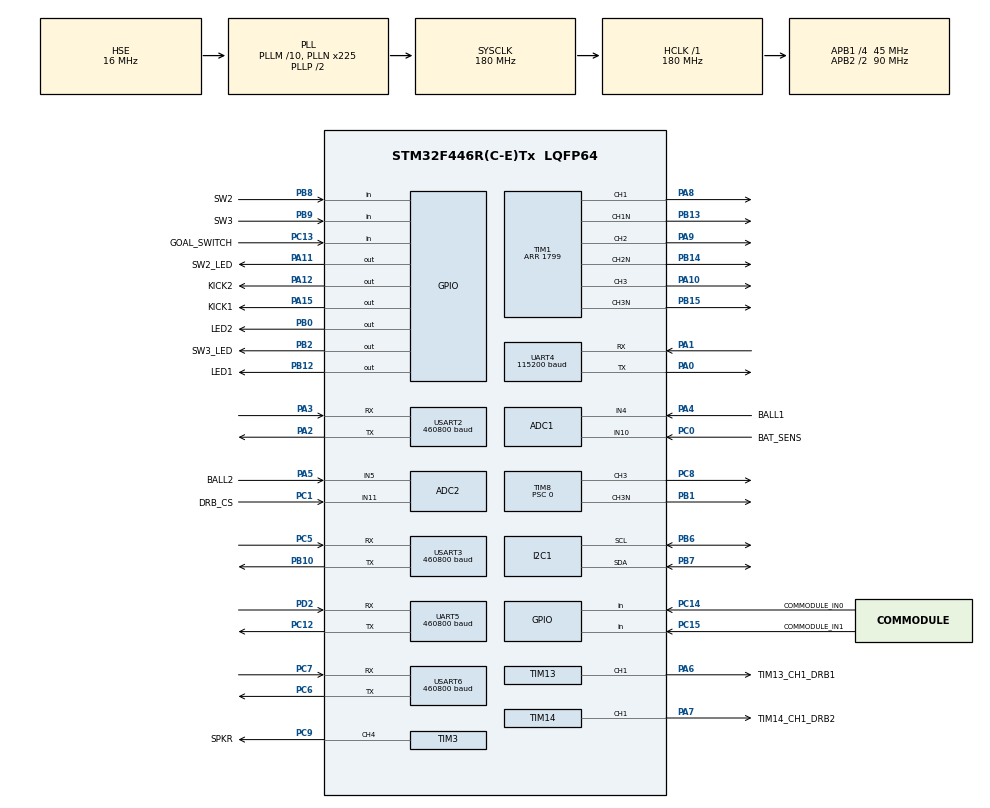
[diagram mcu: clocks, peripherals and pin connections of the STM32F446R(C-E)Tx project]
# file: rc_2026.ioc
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ADC1.Channel-0\#ChannelRegularConversion=ADC_CHANNEL_4
ADC1.ClockPrescaler=ADC_CLOCK_SYNC_PCLK_DIV4
ADC1.NbrOfConversionFlag=1
ADC1.Rank-0\#ChannelRegularConversion=1
ADC1.SamplingTime-0\#ChannelRegularConversion=ADC_SAMPLETIME_3CYCLES
ADC1.master=1
ADC2.Channel-0\#ChannelRegularConversion=ADC_CHANNEL_5
ADC2.ClockPrescaler=ADC_CLOCK_SYNC_PCLK_DIV4
ADC2.NbrOfConversionFlag=1
ADC2.Rank-0\#ChannelRegularConversion=1
ADC2.SamplingTime-0\#ChannelRegularConversion=ADC_SAMPLETIME_3CYCLES
Dma.Request0=USART6_RX
Dma.USART6_RX.0.Direction=DMA_PERIPH_TO_MEMORY
Dma.USART6_RX.0.FIFOMode=DMA_FIFOMODE_DISABLE
Dma.USART6_RX.0.Instance=DMA2_Stream1
Dma.USART6_RX.0.MemDataAlignment=DMA_MDATAALIGN_BYTE
Dma.USART6_RX.0.MemInc=DMA_MINC_ENABLE
Dma.USART6_RX.0.Mode=DMA_NORMAL
Dma.USART6_RX.0.PeriphDataAlignment=DMA_PDATAALIGN_BYTE
Dma.USART6_RX.0.PeriphInc=DMA_PINC_DISABLE
Dma.USART6_RX.0.Priority=DMA_PRIORITY_LOW
Mcu.Family=STM32F4
Mcu.Name=STM32F446R(C-E)Tx
Mcu.Package=LQFP64
NVIC.DMA2_Stream1_IRQn=true\:0\:0\:false\:false\:true\:false\:true\:true
NVIC.PriorityGroup=NVIC_PRIORITYGROUP_4
NVIC.RCC_IRQn=true\:0\:0\:false\:false\:true\:true\:false\:true
NVIC.TIM1_BRK_TIM9_IRQn=true\:0\:0\:false\:false\:true\:true\:true\:true
NVIC.TIM6_DAC_IRQn=true\:15\:0\:true\:false\:true\:true\:true\:true
NVIC.TIM8_TRG_COM_TIM14_IRQn=true\:0\:0\:false\:false\:true\:true\:true\:true
NVIC.UART4_IRQn=true\:0\:0\:false\:false\:true\:true\:true\:true
NVIC.UART5_IRQn=true\:0\:0\:false\:false\:true\:true\:true\:true
NVIC.USART2_IRQn=true\:1\:0\:true\:false\:true\:true\:true\:true
NVIC.USART3_IRQn=true\:0\:0\:false\:false\:true\:true\:true\:true
NVIC.USART6_IRQn=true\:0\:0\:false\:false\:true\:true\:true\:true
PA0-WKUP.Mode=Asynchronous
PA0-WKUP.Signal=UART4_TX
PA1.Mode=Asynchronous
PA1.Signal=UART4_RX
PA10.Signal=S_TIM1_CH3
PA11.GPIO_Label=SW2_LED
PA11.Signal=GPIO_Output
PA12.GPIO_Label=KICK2
PA12.GPIO_ModeDefaultOutputPP=GPIO_MODE_OUTPUT_PP
PA12.GPIO_PuPd=GPIO_NOPULL
PA12.PinState=GPIO_PIN_RESET
PA12.Signal=GPIO_Output
PA13.Mode=Serial_Wire
PA13.Signal=SYS_JTMS-SWDIO
PA14.Mode=Serial_Wire
PA14.Signal=SYS_JTCK-SWCLK
PA15.GPIO_Label=KICK1
PA15.GPIO_ModeDefaultOutputPP=GPIO_MODE_OUTPUT_PP
PA15.GPIO_PuPd=GPIO_NOPULL
PA15.Signal=GPIO_Output
PA2.Mode=Asynchronous
PA2.Signal=USART2_TX
PA3.Mode=Asynchronous
PA3.Signal=USART2_RX
PA4.GPIO_Label=BALL1
PA4.Signal=ADCx_IN4
PA5.GPIO_Label=BALL2
PA5.Signal=ADCx_IN5
PA6.GPIO_Label=TIM13_CH1_DRB1
PA6.Signal=S_TIM13_CH1
PA7.GPIO_Label=TIM14_CH1_DRB2
PA7.Signal=S_TIM14_CH1
PA8.Signal=S_TIM1_CH1
PA9.Signal=S_TIM1_CH2
PB0.GPIO_Label=LED2
PB0.Signal=GPIO_Output
PB1.Mode=PWM Generation3 CH3 CH3N
PB1.Signal=TIM8_CH3N
PB10.Mode=Asynchronous
PB10.Signal=USART3_TX
PB12.GPIO_Label=LED1
PB12.Signal=GPIO_Output
PB13.Mode=PWM Generation1 CH1 CH1N
PB13.Signal=TIM1_CH1N
PB14.Mode=PWM Generation2 CH2 CH2N
PB14.Signal=TIM1_CH2N
PB15.Mode=PWM Generation3 CH3 CH3N
PB15.Signal=TIM1_CH3N
PB2.GPIO_Label=SW3_LED
PB2.Signal=GPIO_Output
PB6.Mode=I2C
PB6.Signal=I2C1_SCL
PB7.Mode=I2C
PB7.Signal=I2C1_SDA
PB8.GPIO_Label=SW2
PB8.Signal=GPIO_Input
PB9.GPIO_Label=SW3
PB9.Signal=GPIO_Input
PC0.GPIO_Label=BAT_SENS
PC0.Signal=ADCx_IN10
PC1.GPIO_Label=DRB_CS
PC1.Signal=ADCx_IN11
PC12.Mode=Asynchronous
PC12.Signal=UART5_TX
PC13.GPIO_Label=GOAL_SWITCH
PC13.Signal=GPIO_Input
PC14-OSC32_IN.GPIO_Label=COMMODULE_IN0
PC14-OSC32_IN.Signal=GPIO_Input
PC15-OSC32_OUT.GPIO_Label=COMMODULE_IN1
PC15-OSC32_OUT.Signal=GPIO_Input
PC5.Mode=Asynchronous
PC5.Signal=USART3_RX
PC6.GPIO_PuPd=GPIO_NOPULL
PC6.Mode=Asynchronous
PC6.Signal=USART6_TX
PC7.Mode=Asynchronous
PC7.Signal=USART6_RX
PC8.Signal=S_TIM8_CH3
PC9.GPIO_Label=SPKR
PC9.Signal=S_TIM3_CH4
PD2.Mode=Asynchronous
PD2.Signal=UART5_RX
PH0-OSC_IN.Mode=HSE-External-Oscillator
PH0-OSC_IN.Signal=RCC_OSC_IN
PH1-OSC_OUT.Mode=HSE-External-Oscillator
PH1-OSC_OUT.Signal=RCC_OSC_OUT
ProjectManager.HeapSize=0x200
ProjectManager.StackSize=0x400
ProjectManager.TargetToolchain=STM32CubeIDE
RCC.AHBFreq_Value=180000000
RCC.APB1CLKDivider=RCC_HCLK_DIV4
RCC.APB1Freq_Value=45000000
RCC.APB1TimFreq_Value=90000000
RCC.APB2CLKDivider=RCC_HCLK_DIV2
RCC.APB2Freq_Value=90000000
RCC.APB2TimFreq_Value=180000000
RCC.CortexFreq_Value=180000000
RCC.HCLKFreq_Value=180000000
RCC.HSE_Timout=5000
RCC.HSE_VALUE=16000000
RCC.HSICalibrationValue=31
RCC.PLLM=10
RCC.PLLN=225
RCC.PLLSAIM=20
RCC.PLLSourceVirtual=RCC_PLLSOURCE_HSE
RCC.SYSCLKFreq_VALUE=180000000
RCC.SYSCLKSource=RCC_SYSCLKSOURCE_PLLCLK
RCC.USBFreq_Value=180000000
RCC.VCOOutputFreq_Value=360000000
SH.ADCx_IN10.0=ADC1_IN10,IN10
SH.ADCx_IN11.0=ADC2_IN11,IN11
SH.ADCx_IN4.0=ADC1_IN4,IN4
SH.ADCx_IN5.0=ADC2_IN5,IN5
SH.S_TIM13_CH1.0=TIM13_CH1,PWM Generation1 CH1
SH.S_TIM14_CH1.0=TIM14_CH1,PWM Generation1 CH1
SH.S_TIM1_CH1.0=TIM1_CH1,PWM Generation1 CH1 CH1N
SH.S_TIM1_CH2.0=TIM1_CH2,PWM Generation2 CH2 CH2N
SH.S_TIM1_CH3.0=TIM1_CH3,PWM Generation3 CH3 CH3N
SH.S_TIM3_CH4.0=TIM3_CH4,PWM Generation4 CH4
SH.S_TIM8_CH3.0=TIM8_CH3,PWM Generation3 CH3 CH3N
TIM1.Channel-PWM\ Generation1\ CH1\ CH1N=TIM_CHANNEL_1
TIM1.Channel-PWM\ Generation2\ CH2\ CH2N=TIM_CHANNEL_2
TIM1.Channel-PWM\ Generation3\ CH3\ CH3N=TIM_CHANNEL_3
TIM1.Period=1799
TIM12.Period=100
TIM12.Prescaler=45
TIM13.Channel=TIM_CHANNEL_1
TIM13.Period=100
TIM13.Prescaler=180
TIM14.Channel=TIM_CHANNEL_1
TIM14.Period=100
TIM14.Prescaler=180
TIM2.Period=100
TIM2.Prescaler=45
TIM3.Channel-PWM\ Generation4\ CH4=TIM_CHANNEL_4
TIM3.Period=369
TIM3.Prescaler=89
TIM4.Period=100
TIM4.Prescaler=45
TIM5.Period=65535
TIM5.Prescaler=90
TIM6.Period=200
TIM6.Prescaler=9000
TIM7.Prescaler=45000
TIM8.Channel-PWM\ Generation3\ CH3\ CH3N=TIM_CHANNEL_3
TIM8.Period=1799
TIM8.Prescaler=0
TIM9.Period=9999
TIM9.Prescaler=17999
UART4.BaudRate=115200
UART4.VirtualMode=Asynchronous
UART5.BaudRate=460800
UART5.VirtualMode=Asynchronous
USART2.BaudRate=460800
USART2.VirtualMode=VM_ASYNC
USART3.BaudRate=460800
USART3.VirtualMode=VM_ASYNC
USART6.BaudRate=460800
USART6.VirtualMode=VM_ASYNC
VP_TIM12_VS_ClockSourceINT.Mode=Internal
VP_TIM13_VS_ClockSourceINT.Mode=Enable_Timer
VP_TIM14_VS_ClockSourceINT.Mode=Enable_Timer
VP_TIM2_VS_ClockSourceINT.Mode=Internal
VP_TIM3_VS_ClockSourceINT.Mode=Internal
VP_TIM4_VS_ClockSourceINT.Mode=Internal
VP_TIM5_VS_ClockSourceINT.Mode=Internal
VP_TIM6_VS_ClockSourceINT.Mode=Enable_Timer
VP_TIM7_VS_ClockSourceINT.Mode=Enable_Timer
VP_TIM8_VS_ClockSourceINT.Mode=Internal
VP_TIM9_VS_ClockSourceINT.Mode=Internal
board=custom

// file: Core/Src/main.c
/* USER CODE BEGIN Header */
/**
  ******************************************************************************
  * @file           : main.c
  * @brief          : Main program body
  ******************************************************************************
  * @attention
  *
  * Copyright (c) 2026 STMicroelectronics.
  * All rights reserved.
  *
  * This software is licensed under terms that can be found in the LICENSE file
  * in the root directory of this software component.
  * If no LICENSE file comes with this software, it is provided AS-IS.
  *
  ******************************************************************************
  */
/* USER CODE END Header */
#include "main.h"

/* USER CODE BEGIN Includes */
  #include "rc_api.h"
  /* USER CODE END Includes */

ADC_HandleTypeDef hadc1;
ADC_HandleTypeDef hadc2;

I2C_HandleTypeDef hi2c1;

TIM_HandleTypeDef htim1;
TIM_HandleTypeDef htim2;
TIM_HandleTypeDef htim3;
TIM_HandleTypeDef htim4;
TIM_HandleTypeDef htim5;
TIM_HandleTypeDef htim6;
TIM_HandleTypeDef htim7;
TIM_HandleTypeDef htim8;
TIM_HandleTypeDef htim9;
TIM_HandleTypeDef htim12;
TIM_HandleTypeDef htim13;
TIM_HandleTypeDef htim14;

UART_HandleTypeDef huart4;
UART_HandleTypeDef huart5;
UART_HandleTypeDef huart2;
UART_HandleTypeDef huart3;
UART_HandleTypeDef huart6;
DMA_HandleTypeDef hdma_usart6_rx;

void SystemClock_Config(void);
static void MX_GPIO_Init(void);
static void MX_DMA_Init(void);
static void MX_UART4_Init(void);
static void MX_UART5_Init(void);
static void MX_USART2_UART_Init(void);
static void MX_USART3_UART_Init(void);
static void MX_USART6_UART_Init(void);
static void MX_TIM14_Init(void);
static void MX_TIM6_Init(void);
static void MX_TIM2_Init(void);
static void MX_TIM3_Init(void);
static void MX_TIM4_Init(void);
static void MX_TIM12_Init(void);
static void MX_ADC1_Init(void);
static void MX_ADC2_Init(void);
static void MX_TIM13_Init(void);
static void MX_TIM8_Init(void);
static void MX_TIM5_Init(void);
static void MX_TIM7_Init(void);
static void MX_I2C1_Init(void);
static void MX_TIM1_Init(void);
static void MX_TIM9_Init(void);

int main(void)
{

  /* MCU Configuration--------------------------------------------------------*/

  /* Reset of all peripherals, Initializes the Flash interface and the Systick. */
  HAL_Init();

  /* Configure the system clock */
  SystemClock_Config();

  /* Initialize all configured peripherals */
  MX_GPIO_Init();
  MX_DMA_Init();
  MX_UART4_Init();
  MX_UART5_Init();
  MX_USART2_UART_Init();
  MX_USART3_UART_Init();
  MX_USART6_UART_Init();
  MX_TIM14_Init();
  MX_TIM6_Init();
  MX_TIM2_Init();
  MX_TIM3_Init();
  MX_TIM4_Init();
  MX_TIM12_Init();
  MX_ADC1_Init();
  MX_ADC2_Init();
  MX_TIM13_Init();
  MX_TIM8_Init();
  MX_TIM5_Init();
  MX_TIM7_Init();
  MX_I2C1_Init();
  MX_TIM1_Init();
  MX_TIM9_Init();
  /* USER CODE BEGIN 2 */
  rc_init();
  /* USER CODE END 2 */

  /* Infinite loop */
  while (1)
  {

    /* USER CODE BEGIN 3 */
    rc_poll();
  }
  /* USER CODE END 3 */
}

void SystemClock_Config(void)
{
  RCC_OscInitTypeDef RCC_OscInitStruct = {0};
  RCC_ClkInitTypeDef RCC_ClkInitStruct = {0};

  /** Configure the main internal regulator output voltage
  */
  __HAL_RCC_PWR_CLK_ENABLE();
  __HAL_PWR_VOLTAGESCALING_CONFIG(PWR_REGULATOR_VOLTAGE_SCALE1);

  /** Initializes the RCC Oscillators according to the specified parameters
  * in the RCC_OscInitTypeDef structure.
  */
  RCC_OscInitStruct.OscillatorType = RCC_OSCILLATORTYPE_HSE;
  RCC_OscInitStruct.HSEState = RCC_HSE_ON;
  RCC_OscInitStruct.PLL.PLLState = RCC_PLL_ON;
  RCC_OscInitStruct.PLL.PLLSource = RCC_PLLSOURCE_HSE;
  RCC_OscInitStruct.PLL.PLLM = 10;
  RCC_OscInitStruct.PLL.PLLN = 225;
  RCC_OscInitStruct.PLL.PLLP = RCC_PLLP_DIV2;
  RCC_OscInitStruct.PLL.PLLQ = 2;
  RCC_OscInitStruct.PLL.PLLR = 2;
  if (HAL_RCC_OscConfig(&RCC_OscInitStruct) != HAL_OK)
  {
    Error_Handler();
  }

  /** Activate the Over-Drive mode
  */
  if (HAL_PWREx_EnableOverDrive() != HAL_OK)
  {
    Error_Handler();
  }

  /** Initializes the CPU, AHB and APB buses clocks
  */
  RCC_ClkInitStruct.ClockType = RCC_CLOCKTYPE_HCLK|RCC_CLOCKTYPE_SYSCLK
                              |RCC_CLOCKTYPE_PCLK1|RCC_CLOCKTYPE_PCLK2;
  RCC_ClkInitStruct.SYSCLKSource = RCC_SYSCLKSOURCE_PLLCLK;
  RCC_ClkInitStruct.AHBCLKDivider = RCC_SYSCLK_DIV1;
  RCC_ClkInitStruct.APB1CLKDivider = RCC_HCLK_DIV4;
  RCC_ClkInitStruct.APB2CLKDivider = RCC_HCLK_DIV2;

  if (HAL_RCC_ClockConfig(&RCC_ClkInitStruct, FLASH_LATENCY_5) != HAL_OK)
  {
    Error_Handler();
  }
}

static void MX_ADC1_Init(void)
{

  ADC_ChannelConfTypeDef sConfig = {0};

  /** Configure the global features of the ADC (Clock, Resolution, Data Alignment and number of conversion)
  */
  hadc1.Instance = ADC1;
  hadc1.Init.ClockPrescaler = ADC_CLOCK_SYNC_PCLK_DIV4;
  hadc1.Init.Resolution = ADC_RESOLUTION_12B;
  hadc1.Init.ScanConvMode = DISABLE;
  hadc1.Init.ContinuousConvMode = DISABLE;
  hadc1.Init.DiscontinuousConvMode = DISABLE;
  hadc1.Init.ExternalTrigConvEdge = ADC_EXTERNALTRIGCONVEDGE_NONE;
  hadc1.Init.ExternalTrigConv = ADC_SOFTWARE_START;
  hadc1.Init.DataAlign = ADC_DATAALIGN_RIGHT;
  hadc1.Init.NbrOfConversion = 1;
  hadc1.Init.DMAContinuousRequests = DISABLE;
  hadc1.Init.EOCSelection = ADC_EOC_SINGLE_CONV;
  if (HAL_ADC_Init(&hadc1) != HAL_OK)
  {
    Error_Handler();
  }

  /** Configure for the selected ADC regular channel its corresponding rank in the sequencer and its sample time.
  */
  sConfig.Channel = ADC_CHANNEL_4;
  sConfig.Rank = 1;
  sConfig.SamplingTime = ADC_SAMPLETIME_3CYCLES;
  if (HAL_ADC_ConfigChannel(&hadc1, &sConfig) != HAL_OK)
  {
    Error_Handler();
  }

}

static void MX_ADC2_Init(void)
{

  ADC_ChannelConfTypeDef sConfig = {0};

  /** Configure the global features of the ADC (Clock, Resolution, Data Alignment and number of conversion)
  */
  hadc2.Instance = ADC2;
  hadc2.Init.ClockPrescaler = ADC_CLOCK_SYNC_PCLK_DIV4;
  hadc2.Init.Resolution = ADC_RESOLUTION_12B;
  hadc2.Init.ScanConvMode = DISABLE;
  hadc2.Init.ContinuousConvMode = DISABLE;
  hadc2.Init.DiscontinuousConvMode = DISABLE;
  hadc2.Init.ExternalTrigConvEdge = ADC_EXTERNALTRIGCONVEDGE_NONE;
  hadc2.Init.ExternalTrigConv = ADC_SOFTWARE_START;
  hadc2.Init.DataAlign = ADC_DATAALIGN_RIGHT;
  hadc2.Init.NbrOfConversion = 1;
  hadc2.Init.DMAContinuousRequests = DISABLE;
  hadc2.Init.EOCSelection = ADC_EOC_SINGLE_CONV;
  if (HAL_ADC_Init(&hadc2) != HAL_OK)
  {
    Error_Handler();
  }

  /** Configure for the selected ADC regular channel its corresponding rank in the sequencer and its sample time.
  */
  sConfig.Channel = ADC_CHANNEL_5;
  sConfig.Rank = 1;
  sConfig.SamplingTime = ADC_SAMPLETIME_3CYCLES;
  if (HAL_ADC_ConfigChannel(&hadc2, &sConfig) != HAL_OK)
  {
    Error_Handler();
  }

}

static void MX_I2C1_Init(void)
{

  hi2c1.Instance = I2C1;
  hi2c1.Init.ClockSpeed = 100000;
  hi2c1.Init.DutyCycle = I2C_DUTYCYCLE_2;
  hi2c1.Init.OwnAddress1 = 0;
  hi2c1.Init.AddressingMode = I2C_ADDRESSINGMODE_7BIT;
  hi2c1.Init.DualAddressMode = I2C_DUALADDRESS_DISABLE;
  hi2c1.Init.OwnAddress2 = 0;
  hi2c1.Init.GeneralCallMode = I2C_GENERALCALL_DISABLE;
  hi2c1.Init.NoStretchMode = I2C_NOSTRETCH_DISABLE;
  if (HAL_I2C_Init(&hi2c1) != HAL_OK)
  {
    Error_Handler();
  }

}

static void MX_TIM1_Init(void)
{

  TIM_MasterConfigTypeDef sMasterConfig = {0};
  TIM_OC_InitTypeDef sConfigOC = {0};
  TIM_BreakDeadTimeConfigTypeDef sBreakDeadTimeConfig = {0};

  htim1.Instance = TIM1;
  htim1.Init.Prescaler = 0;
  htim1.Init.CounterMode = TIM_COUNTERMODE_UP;
  htim1.Init.Period = 1799;
  htim1.Init.ClockDivision = TIM_CLOCKDIVISION_DIV1;
  htim1.Init.RepetitionCounter = 0;
  htim1.Init.AutoReloadPreload = TIM_AUTORELOAD_PRELOAD_DISABLE;
  if (HAL_TIM_PWM_Init(&htim1) != HAL_OK)
  {
    Error_Handler();
  }
  sMasterConfig.MasterOutputTrigger = TIM_TRGO_RESET;
  sMasterConfig.MasterSlaveMode = TIM_MASTERSLAVEMODE_DISABLE;
  if (HAL_TIMEx_MasterConfigSynchronization(&htim1, &sMasterConfig) != HAL_OK)
  {
    Error_Handler();
  }
  sConfigOC.OCMode = TIM_OCMODE_PWM1;
  sConfigOC.Pulse = 0;
  sConfigOC.OCPolarity = TIM_OCPOLARITY_HIGH;
  sConfigOC.OCNPolarity = TIM_OCNPOLARITY_HIGH;
  sConfigOC.OCFastMode = TIM_OCFAST_DISABLE;
  sConfigOC.OCIdleState = TIM_OCIDLESTATE_RESET;
  sConfigOC.OCNIdleState = TIM_OCNIDLESTATE_RESET;
  if (HAL_TIM_PWM_ConfigChannel(&htim1, &sConfigOC, TIM_CHANNEL_1) != HAL_OK)
  {
    Error_Handler();
  }
  if (HAL_TIM_PWM_ConfigChannel(&htim1, &sConfigOC, TIM_CHANNEL_2) != HAL_OK)
  {
    Error_Handler();
  }
  if (HAL_TIM_PWM_ConfigChannel(&htim1, &sConfigOC, TIM_CHANNEL_3) != HAL_OK)
  {
    Error_Handler();
  }
  sBreakDeadTimeConfig.OffStateRunMode = TIM_OSSR_DISABLE;
  sBreakDeadTimeConfig.OffStateIDLEMode = TIM_OSSI_DISABLE;
  sBreakDeadTimeConfig.LockLevel = TIM_LOCKLEVEL_OFF;
  sBreakDeadTimeConfig.DeadTime = 0;
  sBreakDeadTimeConfig.BreakState = TIM_BREAK_DISABLE;
  sBreakDeadTimeConfig.BreakPolarity = TIM_BREAKPOLARITY_HIGH;
  sBreakDeadTimeConfig.AutomaticOutput = TIM_AUTOMATICOUTPUT_DISABLE;
  if (HAL_TIMEx_ConfigBreakDeadTime(&htim1, &sBreakDeadTimeConfig) != HAL_OK)
  {
    Error_Handler();
  }
  HAL_TIM_MspPostInit(&htim1);

}

static void MX_TIM2_Init(void)
{

  TIM_ClockConfigTypeDef sClockSourceConfig = {0};
  TIM_MasterConfigTypeDef sMasterConfig = {0};

  htim2.Instance = TIM2;
  htim2.Init.Prescaler = 45;
  htim2.Init.CounterMode = TIM_COUNTERMODE_UP;
  htim2.Init.Period = 100;
  htim2.Init.ClockDivision = TIM_CLOCKDIVISION_DIV1;
  htim2.Init.AutoReloadPreload = TIM_AUTORELOAD_PRELOAD_DISABLE;
  if (HAL_TIM_Base_Init(&htim2) != HAL_OK)
  {
    Error_Handler();
  }
  sClockSourceConfig.ClockSource = TIM_CLOCKSOURCE_INTERNAL;
  if (HAL_TIM_ConfigClockSource(&htim2, &sClockSourceConfig) != HAL_OK)
  {
    Error_Handler();
  }
  sMasterConfig.MasterOutputTrigger = TIM_TRGO_RESET;
  sMasterConfig.MasterSlaveMode = TIM_MASTERSLAVEMODE_DISABLE;
  if (HAL_TIMEx_MasterConfigSynchronization(&htim2, &sMasterConfig) != HAL_OK)
  {
    Error_Handler();
  }

}

static void MX_TIM3_Init(void)
{

  TIM_ClockConfigTypeDef sClockSourceConfig = {0};
  TIM_MasterConfigTypeDef sMasterConfig = {0};
  TIM_OC_InitTypeDef sConfigOC = {0};

  htim3.Instance = TIM3;
  htim3.Init.Prescaler = 89;
  htim3.Init.CounterMode = TIM_COUNTERMODE_UP;
  htim3.Init.Period = 369;
  htim3.Init.ClockDivision = TIM_CLOCKDIVISION_DIV1;
  htim3.Init.AutoReloadPreload = TIM_AUTORELOAD_PRELOAD_DISABLE;
  if (HAL_TIM_Base_Init(&htim3) != HAL_OK)
  {
    Error_Handler();
  }
  sClockSourceConfig.ClockSource = TIM_CLOCKSOURCE_INTERNAL;
  if (HAL_TIM_ConfigClockSource(&htim3, &sClockSourceConfig) != HAL_OK)
  {
    Error_Handler();
  }
  if (HAL_TIM_PWM_Init(&htim3) != HAL_OK)
  {
    Error_Handler();
  }
  sMasterConfig.MasterOutputTrigger = TIM_TRGO_RESET;
  sMasterConfig.MasterSlaveMode = TIM_MASTERSLAVEMODE_DISABLE;
  if (HAL_TIMEx_MasterConfigSynchronization(&htim3, &sMasterConfig) != HAL_OK)
  {
    Error_Handler();
  }
  sConfigOC.OCMode = TIM_OCMODE_PWM1;
  sConfigOC.Pulse = 0;
  sConfigOC.OCPolarity = TIM_OCPOLARITY_HIGH;
  sConfigOC.OCFastMode = TIM_OCFAST_DISABLE;
  if (HAL_TIM_PWM_ConfigChannel(&htim3, &sConfigOC, TIM_CHANNEL_4) != HAL_OK)
  {
    Error_Handler();
  }
  HAL_TIM_MspPostInit(&htim3);

}

static void MX_TIM4_Init(void)
{

  TIM_ClockConfigTypeDef sClockSourceConfig = {0};
  TIM_MasterConfigTypeDef sMasterConfig = {0};

  htim4.Instance = TIM4;
  htim4.Init.Prescaler = 45;
  htim4.Init.CounterMode = TIM_COUNTERMODE_UP;
  htim4.Init.Period = 100;
  htim4.Init.ClockDivision = TIM_CLOCKDIVISION_DIV1;
  htim4.Init.AutoReloadPreload = TIM_AUTORELOAD_PRELOAD_DISABLE;
  if (HAL_TIM_Base_Init(&htim4) != HAL_OK)
  {
    Error_Handler();
  }
  sClockSourceConfig.ClockSource = TIM_CLOCKSOURCE_INTERNAL;
  if (HAL_TIM_ConfigClockSource(&htim4, &sClockSourceConfig) != HAL_OK)
  {
    Error_Handler();
  }
  sMasterConfig.MasterOutputTrigger = TIM_TRGO_RESET;
  sMasterConfig.MasterSlaveMode = TIM_MASTERSLAVEMODE_DISABLE;
  if (HAL_TIMEx_MasterConfigSynchronization(&htim4, &sMasterConfig) != HAL_OK)
  {
    Error_Handler();
  }

}

static void MX_TIM5_Init(void)
{

  TIM_ClockConfigTypeDef sClockSourceConfig = {0};
  TIM_MasterConfigTypeDef sMasterConfig = {0};

  htim5.Instance = TIM5;
  htim5.Init.Prescaler = 90;
  htim5.Init.CounterMode = TIM_COUNTERMODE_UP;
  htim5.Init.Period = 65535;
  htim5.Init.ClockDivision = TIM_CLOCKDIVISION_DIV1;
  htim5.Init.AutoReloadPreload = TIM_AUTORELOAD_PRELOAD_DISABLE;
  if (HAL_TIM_Base_Init(&htim5) != HAL_OK)
  {
    Error_Handler();
  }
  sClockSourceConfig.ClockSource = TIM_CLOCKSOURCE_INTERNAL;
  if (HAL_TIM_ConfigClockSource(&htim5, &sClockSourceConfig) != HAL_OK)
  {
    Error_Handler();
  }
  sMasterConfig.MasterOutputTrigger = TIM_TRGO_RESET;
  sMasterConfig.MasterSlaveMode = TIM_MASTERSLAVEMODE_DISABLE;
  if (HAL_TIMEx_MasterConfigSynchronization(&htim5, &sMasterConfig) != HAL_OK)
  {
    Error_Handler();
  }

}

static void MX_TIM6_Init(void)
{

  TIM_MasterConfigTypeDef sMasterConfig = {0};

  htim6.Instance = TIM6;
  htim6.Init.Prescaler = 9000;
  htim6.Init.CounterMode = TIM_COUNTERMODE_UP;
  htim6.Init.Period = 200;
  htim6.Init.AutoReloadPreload = TIM_AUTORELOAD_PRELOAD_DISABLE;
  if (HAL_TIM_Base_Init(&htim6) != HAL_OK)
  {
    Error_Handler();
  }
  sMasterConfig.MasterOutputTrigger = TIM_TRGO_RESET;
  sMasterConfig.MasterSlaveMode = TIM_MASTERSLAVEMODE_DISABLE;
  if (HAL_TIMEx_MasterConfigSynchronization(&htim6, &sMasterConfig) != HAL_OK)
  {
    Error_Handler();
  }

}

static void MX_TIM7_Init(void)
{

  TIM_MasterConfigTypeDef sMasterConfig = {0};

  htim7.Instance = TIM7;
  htim7.Init.Prescaler = 45000;
  htim7.Init.CounterMode = TIM_COUNTERMODE_UP;
  htim7.Init.Period = 65535;
  htim7.Init.AutoReloadPreload = TIM_AUTORELOAD_PRELOAD_DISABLE;
  if (HAL_TIM_Base_Init(&htim7) != HAL_OK)
  {
    Error_Handler();
  }
  sMasterConfig.MasterOutputTrigger = TIM_TRGO_RESET;
  sMasterConfig.MasterSlaveMode = TIM_MASTERSLAVEMODE_DISABLE;
  if (HAL_TIMEx_MasterConfigSynchronization(&htim7, &sMasterConfig) != HAL_OK)
  {
    Error_Handler();
  }

}

static void MX_TIM8_Init(void)
{

  TIM_ClockConfigTypeDef sClockSourceConfig = {0};
  TIM_MasterConfigTypeDef sMasterConfig = {0};
  TIM_OC_InitTypeDef sConfigOC = {0};
  TIM_BreakDeadTimeConfigTypeDef sBreakDeadTimeConfig = {0};

  htim8.Instance = TIM8;
  htim8.Init.Prescaler = 0;
  htim8.Init.CounterMode = TIM_COUNTERMODE_UP;
  htim8.Init.Period = 1799;
  htim8.Init.ClockDivision = TIM_CLOCKDIVISION_DIV1;
  htim8.Init.RepetitionCounter = 0;
  htim8.Init.AutoReloadPreload = TIM_AUTORELOAD_PRELOAD_DISABLE;
  if (HAL_TIM_Base_Init(&htim8) != HAL_OK)
  {
    Error_Handler();
  }
  sClockSourceConfig.ClockSource = TIM_CLOCKSOURCE_INTERNAL;
  if (HAL_TIM_ConfigClockSource(&htim8, &sClockSourceConfig) != HAL_OK)
  {
    Error_Handler();
  }
  if (HAL_TIM_PWM_Init(&htim8) != HAL_OK)
  {
    Error_Handler();
  }
  sMasterConfig.MasterOutputTrigger = TIM_TRGO_RESET;
  sMasterConfig.MasterSlaveMode = TIM_MASTERSLAVEMODE_DISABLE;
  if (HAL_TIMEx_MasterConfigSynchronization(&htim8, &sMasterConfig) != HAL_OK)
  {
    Error_Handler();
  }
  sConfigOC.OCMode = TIM_OCMODE_PWM1;
  sConfigOC.Pulse = 0;
  sConfigOC.OCPolarity = TIM_OCPOLARITY_HIGH;
  sConfigOC.OCNPolarity = TIM_OCNPOLARITY_HIGH;
  sConfigOC.OCFastMode = TIM_OCFAST_DISABLE;
  sConfigOC.OCIdleState = TIM_OCIDLESTATE_RESET;
  sConfigOC.OCNIdleState = TIM_OCNIDLESTATE_RESET;
  if (HAL_TIM_PWM_ConfigChannel(&htim8, &sConfigOC, TIM_CHANNEL_3) != HAL_OK)
  {
    Error_Handler();
  }
  sBreakDeadTimeConfig.OffStateRunMode = TIM_OSSR_DISABLE;
  sBreakDeadTimeConfig.OffStateIDLEMode = TIM_OSSI_DISABLE;
  sBreakDeadTimeConfig.LockLevel = TIM_LOCKLEVEL_OFF;
  sBreakDeadTimeConfig.DeadTime = 0;
  sBreakDeadTimeConfig.BreakState = TIM_BREAK_DISABLE;
  sBreakDeadTimeConfig.BreakPolarity = TIM_BREAKPOLARITY_HIGH;
  sBreakDeadTimeConfig.AutomaticOutput = TIM_AUTOMATICOUTPUT_DISABLE;
  if (HAL_TIMEx_ConfigBreakDeadTime(&htim8, &sBreakDeadTimeConfig) != HAL_OK)
  {
    Error_Handler();
  }
  HAL_TIM_MspPostInit(&htim8);

}

static void MX_TIM9_Init(void)
{

  TIM_ClockConfigTypeDef sClockSourceConfig = {0};

  htim9.Instance = TIM9;
  htim9.Init.Prescaler = 17999;
  htim9.Init.CounterMode = TIM_COUNTERMODE_UP;
  htim9.Init.Period = 9999;
  htim9.Init.ClockDivision = TIM_CLOCKDIVISION_DIV1;
  htim9.Init.AutoReloadPreload = TIM_AUTORELOAD_PRELOAD_DISABLE;
  if (HAL_TIM_Base_Init(&htim9) != HAL_OK)
  {
    Error_Handler();
  }
  sClockSourceConfig.ClockSource = TIM_CLOCKSOURCE_INTERNAL;
  if (HAL_TIM_ConfigClockSource(&htim9, &sClockSourceConfig) != HAL_OK)
  {
    Error_Handler();
  }

}

static void MX_TIM12_Init(void)
{

  TIM_ClockConfigTypeDef sClockSourceConfig = {0};

  htim12.Instance = TIM12;
  htim12.Init.Prescaler = 45;
  htim12.Init.CounterMode = TIM_COUNTERMODE_UP;
  htim12.Init.Period = 100;
  htim12.Init.ClockDivision = TIM_CLOCKDIVISION_DIV1;
  htim12.Init.AutoReloadPreload = TIM_AUTORELOAD_PRELOAD_DISABLE;
  if (HAL_TIM_Base_Init(&htim12) != HAL_OK)
  {
    Error_Handler();
  }
  sClockSourceConfig.ClockSource = TIM_CLOCKSOURCE_INTERNAL;
  if (HAL_TIM_ConfigClockSource(&htim12, &sClockSourceConfig) != HAL_OK)
  {
    Error_Handler();
  }

}

static void MX_TIM13_Init(void)
{

  TIM_OC_InitTypeDef sConfigOC = {0};

  htim13.Instance = TIM13;
  htim13.Init.Prescaler = 180;
  htim13.Init.CounterMode = TIM_COUNTERMODE_UP;
  htim13.Init.Period = 100;
  htim13.Init.ClockDivision = TIM_CLOCKDIVISION_DIV1;
  htim13.Init.AutoReloadPreload = TIM_AUTORELOAD_PRELOAD_DISABLE;
  if (HAL_TIM_Base_Init(&htim13) != HAL_OK)
  {
    Error_Handler();
  }
  if (HAL_TIM_PWM_Init(&htim13) != HAL_OK)
  {
    Error_Handler();
  }
  sConfigOC.OCMode = TIM_OCMODE_PWM1;
  sConfigOC.Pulse = 0;
  sConfigOC.OCPolarity = TIM_OCPOLARITY_HIGH;
  sConfigOC.OCFastMode = TIM_OCFAST_DISABLE;
  if (HAL_TIM_PWM_ConfigChannel(&htim13, &sConfigOC, TIM_CHANNEL_1) != HAL_OK)
  {
    Error_Handler();
  }
  HAL_TIM_MspPostInit(&htim13);

}

static void MX_TIM14_Init(void)
{

  TIM_OC_InitTypeDef sConfigOC = {0};

  htim14.Instance = TIM14;
  htim14.Init.Prescaler = 180;
  htim14.Init.CounterMode = TIM_COUNTERMODE_UP;
  htim14.Init.Period = 100;
  htim14.Init.ClockDivision = TIM_CLOCKDIVISION_DIV1;
  htim14.Init.AutoReloadPreload = TIM_AUTORELOAD_PRELOAD_DISABLE;
  if (HAL_TIM_Base_Init(&htim14) != HAL_OK)
  {
    Error_Handler();
  }
  if (HAL_TIM_PWM_Init(&htim14) != HAL_OK)
  {
    Error_Handler();
  }
  sConfigOC.OCMode = TIM_OCMODE_PWM1;
  sConfigOC.Pulse = 0;
  sConfigOC.OCPolarity = TIM_OCPOLARITY_HIGH;
  sConfigOC.OCFastMode = TIM_OCFAST_DISABLE;
  if (HAL_TIM_PWM_ConfigChannel(&htim14, &sConfigOC, TIM_CHANNEL_1) != HAL_OK)
  {
    Error_Handler();
  }
  HAL_TIM_MspPostInit(&htim14);

}

static void MX_UART4_Init(void)
{

  huart4.Instance = UART4;
  huart4.Init.BaudRate = 115200;
  huart4.Init.WordLength = UART_WORDLENGTH_8B;
  huart4.Init.StopBits = UART_STOPBITS_1;
  huart4.Init.Parity = UART_PARITY_NONE;
  huart4.Init.Mode = UART_MODE_TX_RX;
  huart4.Init.HwFlowCtl = UART_HWCONTROL_NONE;
  huart4.Init.OverSampling = UART_OVERSAMPLING_16;
  if (HAL_UART_Init(&huart4) != HAL_OK)
  {
    Error_Handler();
  }

}

static void MX_UART5_Init(void)
{

  huart5.Instance = UART5;
  huart5.Init.BaudRate = 460800;
  huart5.Init.WordLength = UART_WORDLENGTH_8B;
  huart5.Init.StopBits = UART_STOPBITS_1;
  huart5.Init.Parity = UART_PARITY_NONE;
  huart5.Init.Mode = UART_MODE_TX_RX;
  huart5.Init.HwFlowCtl = UART_HWCONTROL_NONE;
  huart5.Init.OverSampling = UART_OVERSAMPLING_16;
  if (HAL_UART_Init(&huart5) != HAL_OK)
  {
    Error_Handler();
  }

}

static void MX_USART2_UART_Init(void)
{

  huart2.Instance = USART2;
  huart2.Init.BaudRate = 460800;
  huart2.Init.WordLength = UART_WORDLENGTH_8B;
  huart2.Init.StopBits = UART_STOPBITS_1;
  huart2.Init.Parity = UART_PARITY_NONE;
  huart2.Init.Mode = UART_MODE_TX_RX;
  huart2.Init.HwFlowCtl = UART_HWCONTROL_NONE;
  huart2.Init.OverSampling = UART_OVERSAMPLING_16;
  if (HAL_UART_Init(&huart2) != HAL_OK)
  {
    Error_Handler();
  }

}

static void MX_USART3_UART_Init(void)
{

  huart3.Instance = USART3;
  huart3.Init.BaudRate = 460800;
  huart3.Init.WordLength = UART_WORDLENGTH_8B;
  huart3.Init.StopBits = UART_STOPBITS_1;
  huart3.Init.Parity = UART_PARITY_NONE;
  huart3.Init.Mode = UART_MODE_TX_RX;
  huart3.Init.HwFlowCtl = UART_HWCONTROL_NONE;
  huart3.Init.OverSampling = UART_OVERSAMPLING_16;
  if (HAL_UART_Init(&huart3) != HAL_OK)
  {
    Error_Handler();
  }

}

static void MX_USART6_UART_Init(void)
{

  huart6.Instance = USART6;
  huart6.Init.BaudRate = 460800;
  huart6.Init.WordLength = UART_WORDLENGTH_8B;
  huart6.Init.StopBits = UART_STOPBITS_1;
  huart6.Init.Parity = UART_PARITY_NONE;
  huart6.Init.Mode = UART_MODE_TX_RX;
  huart6.Init.HwFlowCtl = UART_HWCONTROL_NONE;
  huart6.Init.OverSampling = UART_OVERSAMPLING_16;
  if (HAL_UART_Init(&huart6) != HAL_OK)
  {
    Error_Handler();
  }

}

static void MX_DMA_Init(void)
{

  /* DMA controller clock enable */
  __HAL_RCC_DMA2_CLK_ENABLE();

  /* DMA interrupt init */
  /* DMA2_Stream1_IRQn interrupt configuration */
  HAL_NVIC_SetPriority(DMA2_Stream1_IRQn, 0, 0);
  HAL_NVIC_EnableIRQ(DMA2_Stream1_IRQn);

}

static void MX_GPIO_Init(void)
{
  GPIO_InitTypeDef GPIO_InitStruct = {0};

  /* GPIO Ports Clock Enable */
  __HAL_RCC_GPIOC_CLK_ENABLE();
  __HAL_RCC_GPIOH_CLK_ENABLE();
  __HAL_RCC_GPIOA_CLK_ENABLE();
  __HAL_RCC_GPIOB_CLK_ENABLE();
  __HAL_RCC_GPIOD_CLK_ENABLE();

  /*Configure GPIO pin Output Level */
  HAL_GPIO_WritePin(GPIOB, LED2_Pin|SW3_LED_Pin|LED1_Pin, GPIO_PIN_RESET);

  /*Configure GPIO pin Output Level */
  HAL_GPIO_WritePin(GPIOA, SW2_LED_Pin|KICK2_Pin|KICK1_Pin, GPIO_PIN_RESET);

  /*Configure GPIO pins : GOAL_SWITCH_Pin COMMODULE_IN0_Pin COMMODULE_IN1_Pin */
  GPIO_InitStruct.Pin = GOAL_SWITCH_Pin|COMMODULE_IN0_Pin|COMMODULE_IN1_Pin;
  GPIO_InitStruct.Mode = GPIO_MODE_INPUT;
  GPIO_InitStruct.Pull = GPIO_NOPULL;
  HAL_GPIO_Init(GPIOC, &GPIO_InitStruct);

  /*Configure GPIO pins : LED2_Pin SW3_LED_Pin LED1_Pin */
  GPIO_InitStruct.Pin = LED2_Pin|SW3_LED_Pin|LED1_Pin;
  GPIO_InitStruct.Mode = GPIO_MODE_OUTPUT_PP;
  GPIO_InitStruct.Pull = GPIO_NOPULL;
  GPIO_InitStruct.Speed = GPIO_SPEED_FREQ_LOW;
  HAL_GPIO_Init(GPIOB, &GPIO_InitStruct);

  /*Configure GPIO pins : SW2_LED_Pin KICK2_Pin KICK1_Pin */
  GPIO_InitStruct.Pin = SW2_LED_Pin|KICK2_Pin|KICK1_Pin;
  GPIO_InitStruct.Mode = GPIO_MODE_OUTPUT_PP;
  GPIO_InitStruct.Pull = GPIO_NOPULL;
  GPIO_InitStruct.Speed = GPIO_SPEED_FREQ_LOW;
  HAL_GPIO_Init(GPIOA, &GPIO_InitStruct);

  /*Configure GPIO pins : SW2_Pin SW3_Pin */
  GPIO_InitStruct.Pin = SW2_Pin|SW3_Pin;
  GPIO_InitStruct.Mode = GPIO_MODE_INPUT;
  GPIO_InitStruct.Pull = GPIO_NOPULL;
  HAL_GPIO_Init(GPIOB, &GPIO_InitStruct);

}

void Error_Handler(void)
{
  /* USER CODE BEGIN Error_Handler_Debug */
  rc_emergency_cutoff();
  __disable_irq();
  while (1) {}
  /* USER CODE END Error_Handler_Debug */
}
